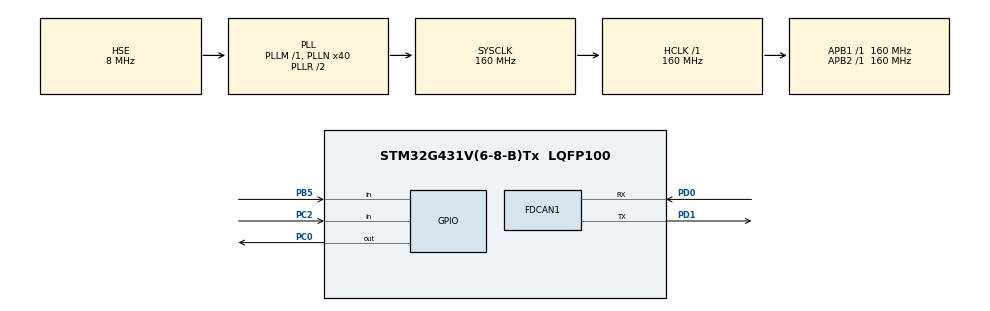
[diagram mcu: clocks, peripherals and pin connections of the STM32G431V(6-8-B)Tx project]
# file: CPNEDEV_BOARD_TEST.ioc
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FDCAN1.CalculateBaudRateNominal=3333333
FDCAN1.CalculateTimeBitNominal=300
FDCAN1.CalculateTimeQuantumNominal=100.0
FDCAN1.DataPrescaler=17
FDCAN1.DataSyncJumpWidth=4
FDCAN1.DataTimeSeg1=15
FDCAN1.DataTimeSeg2=4
FDCAN1.NominalSyncJumpWidth=4
Mcu.Family=STM32G4
Mcu.Name=STM32G431V(6-8-B)Tx
Mcu.Package=LQFP100
NVIC.PriorityGroup=NVIC_PRIORITYGROUP_4
PB5.Signal=GPIO_Input
PC0.Signal=GPIO_Output
PC2.Signal=GPIO_Input
PD0.Mode=FDCAN_Activate
PD0.Signal=FDCAN1_RX
PD1.Mode=FDCAN_Activate
PD1.Signal=FDCAN1_TX
PF0-OSC_IN.Mode=HSE-External-Oscillator
PF0-OSC_IN.Signal=RCC_OSC_IN
PF1-OSC_OUT.Mode=HSE-External-Oscillator
PF1-OSC_OUT.Signal=RCC_OSC_OUT
ProjectManager.HeapSize=0x200
ProjectManager.StackSize=0x400
ProjectManager.TargetToolchain=STM32CubeIDE
RCC.ADC12Freq_Value=160000000
RCC.AHBFreq_Value=160000000
RCC.APB1Freq_Value=160000000
RCC.APB1TimFreq_Value=160000000
RCC.APB2Freq_Value=160000000
RCC.APB2TimFreq_Value=160000000
RCC.CK48CLockSelection=RCC_USBCLKSOURCE_HSI48
RCC.CortexFreq_Value=160000000
RCC.EXTERNAL_CLOCK_VALUE=12288000
RCC.HCLKFreq_Value=160000000
RCC.HSE_VALUE=8000000
RCC.HSI48_VALUE=48000000
RCC.HSI_VALUE=16000000
RCC.LSE_VALUE=32768
RCC.PLLN=40
RCC.PLLQ=RCC_PLLQ_DIV4
RCC.PLLSourceVirtual=RCC_PLLSOURCE_HSE
RCC.SYSCLKFreq_VALUE=160000000
RCC.SYSCLKSource=RCC_SYSCLKSOURCE_PLLCLK
RCC.USBFreq_Value=48000000
RCC.VCOOutputFreq_Value=320000000
VP_RTC_VS_RTC_Activate.Mode=RTC_Enabled
VP_SYS_VS_DBSignals.Mode=DisableDeadBatterySignals
board=custom

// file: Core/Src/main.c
/* USER CODE BEGIN Header */
/**
  ******************************************************************************
  * @file           : main.c
  * @brief          : Main program body
  ******************************************************************************
  * @attention
  *
  * Copyright (c) 2026 STMicroelectronics.
  * All rights reserved.
  *
  * This software is licensed under terms that can be found in the LICENSE file
  * in the root directory of this software component.
  * If no LICENSE file comes with this software, it is provided AS-IS.
  *
  ******************************************************************************
  */
/* USER CODE END Header */
#include "main.h"
#include "fdcan.h"
#include "rtc.h"
#include "gpio.h"

/* USER CODE BEGIN PV */
	FDCAN_TxHeaderTypeDef TxHeader;
	uint8_t TxData[8] = {0};
/* USER CODE END PV */

void SystemClock_Config(void);

int main(void)
{

  /* MCU Configuration--------------------------------------------------------*/

  /* Reset of all peripherals, Initializes the Flash interface and the Systick. */
  HAL_Init();

  /* Configure the system clock */
  SystemClock_Config();

  /* Initialize all configured peripherals */
  MX_GPIO_Init();
  MX_FDCAN1_Init();
  MX_RTC_Init();
  /* USER CODE BEGIN 2 */
  TxHeader.Identifier = 0x123;
  TxHeader.IdType = FDCAN_STANDARD_ID;
  TxHeader.TxFrameType = FDCAN_DATA_FRAME;
  TxHeader.DataLength = FDCAN_DLC_BYTES_8;
  TxHeader.ErrorStateIndicator = FDCAN_ESI_ACTIVE;
  TxHeader.BitRateSwitch = FDCAN_BRS_OFF;
  TxHeader.FDFormat = FDCAN_CLASSIC_CAN;
  TxHeader.TxEventFifoControl = FDCAN_NO_TX_EVENTS;
  TxHeader.MessageMarker = 0;
  if (HAL_FDCAN_Start(&hfdcan1) != HAL_OK){
	  Error_Handler();
  }
  /* USER CODE END 2 */

  /* Infinite loop */
  while (1)
  {
	  HAL_GPIO_TogglePin(GPIOA, GPIO_PIN_8);
	  HAL_Delay(500);
	  TxData[0]++;

	    if (HAL_FDCAN_AddMessageToTxFifoQ(&hfdcan1, &TxHeader, TxData) != HAL_OK)
	    {
	        Error_Handler();
	    }

	    HAL_Delay(2000);
  }
  /* USER CODE END 3 */
}

void SystemClock_Config(void)
{
  RCC_OscInitTypeDef RCC_OscInitStruct = {0};
  RCC_ClkInitTypeDef RCC_ClkInitStruct = {0};

  /** Configure the main internal regulator output voltage
  */
  HAL_PWREx_ControlVoltageScaling(PWR_REGULATOR_VOLTAGE_SCALE1_BOOST);

  /** Initializes the RCC Oscillators according to the specified parameters
  * in the RCC_OscInitTypeDef structure.
  */
  RCC_OscInitStruct.OscillatorType = RCC_OSCILLATORTYPE_LSI|RCC_OSCILLATORTYPE_HSE;
  RCC_OscInitStruct.HSEState = RCC_HSE_ON;
  RCC_OscInitStruct.LSIState = RCC_LSI_ON;
  RCC_OscInitStruct.PLL.PLLState = RCC_PLL_ON;
  RCC_OscInitStruct.PLL.PLLSource = RCC_PLLSOURCE_HSE;
  RCC_OscInitStruct.PLL.PLLM = RCC_PLLM_DIV1;
  RCC_OscInitStruct.PLL.PLLN = 40;
  RCC_OscInitStruct.PLL.PLLP = RCC_PLLP_DIV2;
  RCC_OscInitStruct.PLL.PLLQ = RCC_PLLQ_DIV4;
  RCC_OscInitStruct.PLL.PLLR = RCC_PLLR_DIV2;
  if (HAL_RCC_OscConfig(&RCC_OscInitStruct) != HAL_OK)
  {
    Error_Handler();
  }

  /** Initializes the CPU, AHB and APB buses clocks
  */
  RCC_ClkInitStruct.ClockType = RCC_CLOCKTYPE_HCLK|RCC_CLOCKTYPE_SYSCLK
                              |RCC_CLOCKTYPE_PCLK1|RCC_CLOCKTYPE_PCLK2;
  RCC_ClkInitStruct.SYSCLKSource = RCC_SYSCLKSOURCE_PLLCLK;
  RCC_ClkInitStruct.AHBCLKDivider = RCC_SYSCLK_DIV1;
  RCC_ClkInitStruct.APB1CLKDivider = RCC_HCLK_DIV1;
  RCC_ClkInitStruct.APB2CLKDivider = RCC_HCLK_DIV1;

  if (HAL_RCC_ClockConfig(&RCC_ClkInitStruct, FLASH_LATENCY_4) != HAL_OK)
  {
    Error_Handler();
  }
}

void Error_Handler(void)
{
  __disable_irq();
  while (1)
  {
  }
}
